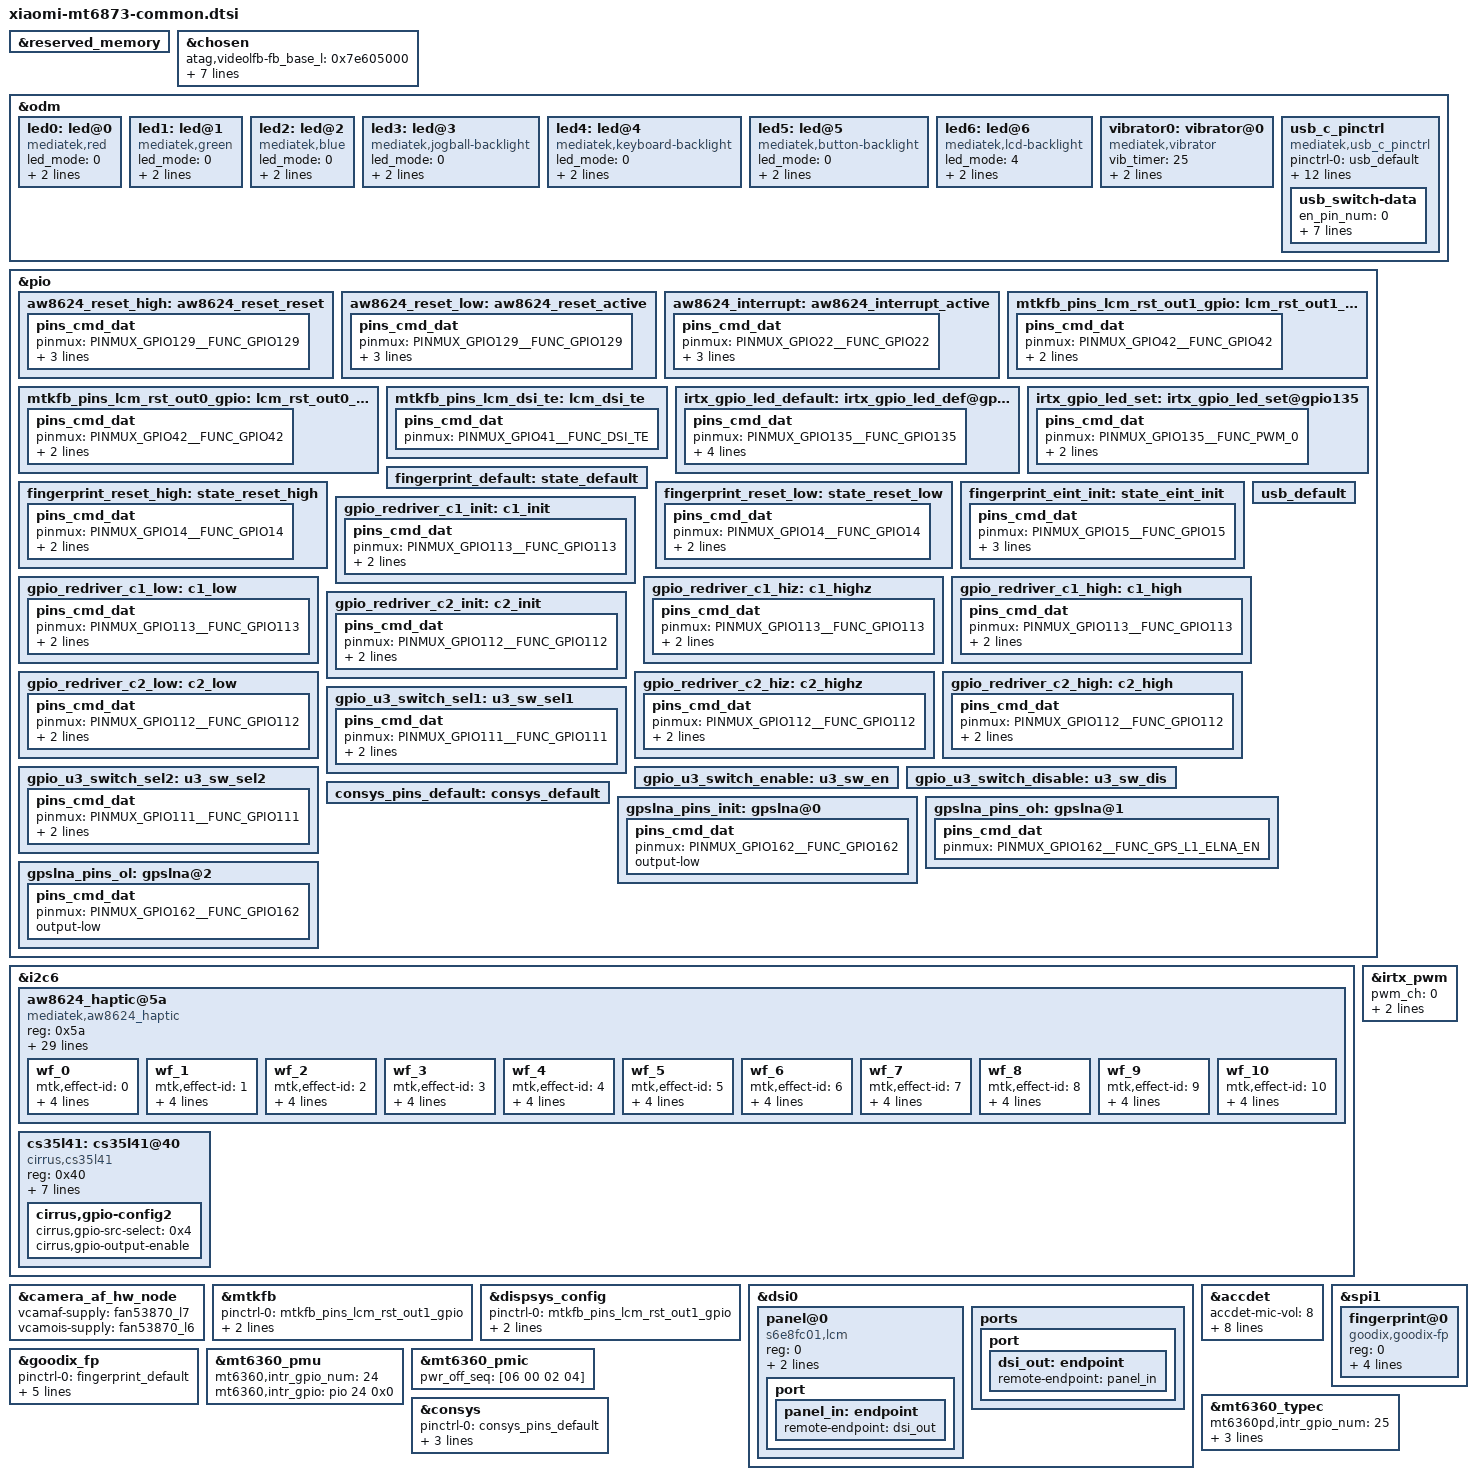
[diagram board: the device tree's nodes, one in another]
/*
 * Mediatek's mt6873 SoC device tree source
 *
 * Copyright (C) 2016 MediaTek Inc.
 * Copyright (C) 2021 XiaoMi, Inc.
 *
 * This program is free software; you can redistribute it and/or modify
 * it under the terms of the GNU General Public License version 2 as
 * published by the Free Software Foundation.
 *
 * This program is distributed in the hope that it will be useful,
 * but WITHOUT ANY WARRANTY; without even the implied warranty of
 * MERCHANTABILITY or FITNESS FOR A PARTICULAR PURPOSE.
 * See http://www.gnu.org/licenses/gpl-2.0.html for more details.
 */
/dts-v1/;
/plugin/;
#include <dt-bindings/interrupt-controller/irq.h>
#include <dt-bindings/interrupt-controller/arm-gic.h>
#include <dt-bindings/pinctrl/mt6873-pinfunc.h>

&reserved_memory {
};

/* chosen */
&chosen {

	atag,videolfb-fb_base_l = <0x7e605000>;
	atag,videolfb-fb_base_h = <0x0>;
	atag,videolfb-islcmfound = <1>;
	atag,videolfb-islcm_inited = <0>;
	atag,videolfb-fps= <6000>;
	atag,videolfb-vramSize= <0x1be0000>;
	atag,videolfb-lcmname=
		"nt35595_fhd_dsi_cmd_truly_nt50358_drv";
};

&odm {
	led0:led@0 {
		compatible = "mediatek,red";
		led_mode = <0>;
		data = <1>;
		pwm_config = <0 0 0 0 0>;
	};
	led1:led@1 {
		compatible = "mediatek,green";
		led_mode = <0>;
		data = <1>;
		pwm_config = <0 0 0 0 0>;
	};
	led2:led@2 {
		compatible = "mediatek,blue";
		led_mode = <0>;
		data = <1>;
		pwm_config = <0 0 0 0 0>;
	};
	led3:led@3 {
		compatible = "mediatek,jogball-backlight";
		led_mode = <0>;
		data = <1>;
		pwm_config = <0 0 0 0 0>;
	};
	led4:led@4 {
		compatible = "mediatek,keyboard-backlight";
		led_mode = <0>;
		data = <1>;
		pwm_config = <0 0 0 0 0>;
	};
	led5:led@5 {
		compatible = "mediatek,button-backlight";
		led_mode = <0>;
		data = <1>;
		pwm_config = <0 0 0 0 0>;
	};
	led6:led@6 {
		compatible = "mediatek,lcd-backlight";
		led_mode = <4>;
		data = <1>;
		pwm_config = <0 1 0 0 0>;
	};
	vibrator0:vibrator@0 {
		compatible = "mediatek,vibrator";
		vib_timer = <25>;
		vib_limit = <9>;
		vib_vol= <9>;
	};
	usb_c_pinctrl:usb_c_pinctrl {
		compatible = "mediatek,usb_c_pinctrl";
	};
};

/* aw8624 start */
&pio {
	aw8624_reset_high: aw8624_reset_reset {
		pins_cmd_dat {
			pinmux = <PINMUX_GPIO129__FUNC_GPIO129>;
			drive-strength = <2>;
			bias-disable;
			output-high;
		};
	};
	aw8624_reset_low: aw8624_reset_active {
		pins_cmd_dat {
			pinmux = <PINMUX_GPIO129__FUNC_GPIO129>;
			drive-strength = <2>;
			bias-disable;
			output-low;
		};
	};
	aw8624_interrupt: aw8624_interrupt_active {
		pins_cmd_dat {
			pinmux = <PINMUX_GPIO22__FUNC_GPIO22>;
			drive-strength = <2>;
			bias-pull-up;
			input-enable;
		};
	};
};

&i2c6 {
    status = "ok";
	aw8624_haptic@5a {
		compatible = "mediatek,aw8624_haptic";
		reg = <0x5a>;
		reset-gpio = <&pio 129 0x0>;
		irq-gpio = <&pio 22 0x0>;
		vib_mode = <0>; /* 0: RAM mode 1:CONT mode*/
		vib_f0_pre = < 2050 >;
		vib_f0_cali_percen = < 7 >;
		vib_cont_drv_lev = < 100 >;
		vib_cont_drv_lvl_ov = < 105 >;
		vib_cont_td = < 0xF06C >;
		vib_cont_zc_thr = < 0x08F8 >;
		vib_cont_num_brk = < 3 >;
		vib_f0_coeff = < 260 >; /*Don't modify it*/
		vib_f0_trace_parameter = < 9 3 1 31 >;
		vib_bemf_config = < 0x10 0x08 0x23 0xf8 >;
		vib_sw_brake = < 0x2c >;
		vib_tset = < 0x11 >;
		vib_func_parameter1 = < 1 >;
		vib_r_spare = < 0x68 >;
		vib_effect_id_boundary = < 10 >;
		vib_gain_flag = < 0 >;
		vib_effect_max = < 170 >;
		vib_trig_config = < 0 1 0 1 2
				0 1 0 1 2
				0 1 0 1 2 >;
		vib_bst_vol_default = < 0x1b >;
		vib_bst_vol_ram = < 0x1b >;
		vib_bst_vol_rtp = < 0x16 >;
		vib_rtp_time = < 20 20 20 20 20 20 20 20 20000 15000
				 15000 20000 25000 15000 30000 25000 20000 20000 20000 20000
				 20000 20000 20000 20000 20000 20000 20000 20000 20000 20000
				 20000 20000 20000 20000 20000 20000 20000 20000 20000 20000
				 20000 20000 20000 20000 20000 20000 20000 20000 20000 20000
				 20000 20000 20000 20000 20000 20000 20000 20000 20000 20000
				 20000 20000 20000 20000 20000 20000 20000 20000 20000 20000
				 20000 20000 20000 20000 20000 20000 20000 20000 20000 20000
				 20000 20000 20000 20000 20000 20000 20000 20000 20000 20000
				 20000 20000 20000 20000 20000 20000 20000 20000 20000 20000
				 20000 20000 20000 20000 20000 20000 20000 20000 20000 20000
				 20000 20000 20000 20000 20000 20000 20000 20000 20000 20000
				 20000 20000 20000 20000 20000 20000 20000 20000 20000 20000
				 20000 20000 20000 20000 20000 20000 20000 20000 20000 20000
				 20000 20000 20000 20000 20000 20000 20000 20000 20000 20000
				 20000 20000 20000 20000 20000 20000 20000 20000 20000 20000
				 20000 20000 20000 20000 20000 20000 20000 20000 20000 20000
				 20000 20000 20000 20000 20000 >;
		pinctrl-names = "aw8624_reset_reset","aw8624_reset_active","aw8624_interrupt_active";
		pinctrl-0 = <&aw8624_reset_low>;
		pinctrl-1 = <&aw8624_reset_high>;
		pinctrl-2 = <&aw8624_interrupt>;
		status = "ok";
		wf_0 {
			/*CLICK*/
			mtk,effect-id = <0>;
			mtk,wf-vmax-mv = <3600>;
			mtk,wf-pattern = [3e 3e];
			mtk,wf-brake-pattern = [02 01 00 00];
			mtk,wf-play-rate-us = <20000>;
		};
		wf_1 {
			/*DOUBLE CLICK*/
			mtk,effect-id = <1>;
			mtk,wf-vmax-mv = <3600>;
			mtk,wf-pattern = [7e 3e];
			mtk,wf-brake-pattern = [03 01 00 00];
			mtk,wf-play-rate-us = <20000>;
		};
		wf_2 {
			/*TICK*/
			mtk,effect-id = <2>;
			mtk,wf-vmax-mv = <3600>;
			mtk,wf-pattern = [7e 3e];
			mtk,wf-brake-pattern = [02 01 00 00];
			mtk,wf-play-rate-us = <13000>;
		};
		wf_3 {
			/*THUD*/
			mtk,effect-id = <3>;
			mtk,wf-vmax-mv = <3600>;
			mtk,wf-pattern = [3e 3e];
			mtk,wf-brake-pattern = [02 01 00 00];
			mtk,wf-play-rate-us = <10000>;
		};
		wf_4 {
			/*POP*/
			mtk,effect-id = <4>;
			mtk,wf-vmax-mv = <3600>;
			mtk,wf-pattern = [3e 3e];
			mtk,wf-brake-pattern = [02 01 00 00];
			mtk,wf-play-rate-us = <28000>;
		};
		wf_5 {
			/*HEAVY CLICK*/
			mtk,effect-id = <5>;
			mtk,wf-vmax-mv = <3600>;
			mtk,wf-pattern = [7e 7e 7e];
			mtk,wf-brake-pattern = [03 03 01 00];
			mtk,wf-play-rate-us = <10000>;
		};
		wf_6 {
			/*CLICK*/
			mtk,effect-id = <6>;
			mtk,wf-vmax-mv = <3600>;
			mtk,wf-pattern = [3e 3e];
			mtk,wf-brake-pattern = [02 01 00 00];
			mtk,wf-play-rate-us = <25000>;
		};
		wf_7 {
			/*DOUBLE CLICK*/
			mtk,effect-id = <7>;
			mtk,wf-vmax-mv = <3600>;
			mtk,wf-pattern = [7e 3e];
			mtk,wf-brake-pattern = [03 01 00 00];
			mtk,wf-play-rate-us = <25000>;
		};
		wf_8 {
			/*TICK*/
			mtk,effect-id = <8>;
			mtk,wf-vmax-mv = <3600>;
			mtk,wf-pattern = [7e 3e];
			mtk,wf-brake-pattern = [02 01 00 00];
			mtk,wf-play-rate-us = <35000>;
		};
		wf_9 {
			/*THUD*/
			mtk,effect-id = <9>;
			mtk,wf-vmax-mv = <3600>;
			mtk,wf-pattern = [3e 3e];
			mtk,wf-brake-pattern = [02 01 00 00];
			mtk,wf-play-rate-us = <15000>;
		};
		wf_10 {
			/*POP*/
			mtk,effect-id = <10>;
			mtk,wf-vmax-mv = <3600>;
			mtk,wf-pattern = [3e 3e];
			mtk,wf-brake-pattern = [02 01 00 00];
			mtk,wf-play-rate-us = <15000>;
		};
	};
};
/* aw8624 end */

/* DISPSYS GPIO standardization */

&pio {
	mtkfb_pins_lcm_rst_out1_gpio: lcm_rst_out1_gpio {
		pins_cmd_dat {
			pinmux = <PINMUX_GPIO42__FUNC_GPIO42>;
			slew-rate = <1>;
			output-high;
		};
	};

	mtkfb_pins_lcm_rst_out0_gpio: lcm_rst_out0_gpio {
		pins_cmd_dat {
			pinmux = <PINMUX_GPIO42__FUNC_GPIO42>;
			slew-rate = <1>;
			output-low;
		};
	};
	mtkfb_pins_lcm_dsi_te: lcm_dsi_te {
		pins_cmd_dat {
			pinmux = <PINMUX_GPIO41__FUNC_DSI_TE>;
		};
	};
};

&camera_af_hw_node {
	vcamaf-supply = <&fan53870_l7>;
	vcamois-supply = <&fan53870_l6>;
	status = "okay";
};

&mtkfb {
	pinctrl-names = "lcm_rst_out1_gpio", "lcm_rst_out0_gpio",
		"mode_te_te";
	pinctrl-0 = <&mtkfb_pins_lcm_rst_out1_gpio>;
	pinctrl-1 = <&mtkfb_pins_lcm_rst_out0_gpio>;
	pinctrl-2 = <&mtkfb_pins_lcm_dsi_te>;
	status = "okay";
};

&dispsys_config {
	pinctrl-names =
		"lcm_rst_out1_gpio", "lcm_rst_out0_gpio",
		"mode_te_te";
	pinctrl-0 = <&mtkfb_pins_lcm_rst_out1_gpio>;
	pinctrl-1 = <&mtkfb_pins_lcm_rst_out0_gpio>;
	pinctrl-2 = <&mtkfb_pins_lcm_dsi_te>;
	status = "okay";
};

&dsi0 {
	status = "okay";
	#address-cells = <1>;
	#size-cells = <0>;
	panel@0 {
		compatible = "s6e8fc01,lcm";
		reg = <0>;
		pm-enable-gpios = <&pio 29 0>;
		reset-gpios = <&pio 42 0>;
		pinctrl-names = "default";
		port {
			panel_in: endpoint {
				remote-endpoint = <&dsi_out>;
			};
		};
	};
	ports {
		port {
			dsi_out: endpoint {
				remote-endpoint = <&panel_in>;
			};
		};
	};
};

/* accdet start */
&accdet {
	/* accdet micbias voltage: 0x09:2.85v 0x08:2.8v 0x07,
	 * 2.7v;0x05,2.5v;0x02,1.9v
	 */
	accdet-mic-vol = <8>;
	/* accdet pwm_width, pwm_thresh, fall_delay, rise_delay
	 * debounce0, debounce1, debounce3, debounce4
	 * eint pwm_width, eint pwm_thresh
	 * eint deb(debounce0, debounce1, debounce2, debounce3), inv_debounce
	 */
	headset-mode-setting = <0x500 0x500 1 0x1f0
				0x800 0x1200 0x20 0x44
				0x4 0x1
				0x5 0x3 0x3 0x7 0xe>;
	accdet-plugout-debounce = <1>;
	/*1:ACC mode, 2:low cost without in bias, 6:low cost with in bias*/
	accdet-mic-mode = <2>;
	/*0--MD_MAX--UP_MAX--DW_MAX*/
	headset-three-key-threshold = <0 80 220 400>;
	headset-three-key-threshold-CDD = <0 121 192 600>;
	/*0--MD_MAX--VOICE_MAX--UP_MAX--DW_MAX*/
	headset-four-key-threshold = <0 58 121 192 400>;

	/* select VTH to 2v and 500k, use internal resitance */
	eint_use_ext_res = <4>;
	status = "okay";
};
/* accdet end */

/* IRTX GPIO Start */
&irtx_pwm {
	pwm_ch = <0>;
	pinctrl-names = "irtx_gpio_led_default", "irtx_gpio_led_set";
	pinctrl-0 = <&irtx_gpio_led_default>;
	pinctrl-1 = <&irtx_gpio_led_set>;
	status = "okay";
};
&pio {
	/* IRTX GPIO Settings -Start */
	/* default: GPIO0, output, high */
	irtx_gpio_led_default:irtx_gpio_led_def@gpio135 {
		pins_cmd_dat {
			pinmux = <PINMUX_GPIO135__FUNC_GPIO135>;
			slew-rate = <1>;
			bias-disable;
			output-low;
			input-schmitt-enable = <0>;
		};
	};

	irtx_gpio_led_set:irtx_gpio_led_set@gpio135 {
		pins_cmd_dat {
			pinmux = <PINMUX_GPIO135__FUNC_PWM_0>;
			slew-rate = <1>;
			output-high;
		};
	};
}; /* IRTX GPIO Settings -End */

/* FINGERPRINT start */
&spi1 {
	#address-cells = <1>;
	#size-cells = <0>;
	fingerprint@0 {
		compatible = "goodix,goodix-fp";
		reg = <0>;
		spi-max-frequency = <8000000>;
		netlink-event = <30>;
		vfp-supply = <&mt_pmic_vfp_ldo_reg>;
		power-type = <1>;
		status = "okay";
	};
};

&goodix_fp {
	pinctrl-names = "default", "reset_high", "reset_low", "eint_init";
	pinctrl-0 = <&fingerprint_default>;
	pinctrl-1 = <&fingerprint_reset_high>;
	pinctrl-2 = <&fingerprint_reset_low>;
	pinctrl-3 = <&fingerprint_eint_init>;
	interrupt-parent = <&pio>;
	interrupts = <15 IRQ_TYPE_EDGE_RISING 15 0>;
	status = "okay";
};

&pio {
	fingerprint_default: state_default {
	};
	fingerprint_reset_high: state_reset_high {
		pins_cmd_dat {
			pinmux = <PINMUX_GPIO14__FUNC_GPIO14>;
			slew-rate = <1>;
			output-high;
		};
	};
	fingerprint_reset_low: state_reset_low {
		pins_cmd_dat {
			pinmux = <PINMUX_GPIO14__FUNC_GPIO14>;
			slew-rate = <1>;
			output-low;
		};
	};
	fingerprint_eint_init: state_eint_init {
		pins_cmd_dat {
			pinmux = <PINMUX_GPIO15__FUNC_GPIO15>;
			slew-rate = <0>;
			bias-pull-up = <MTK_PUPD_SET_R1R0_10>;
			input-schmitt-enable;
		};
	};
};
/* FINGERPRINT end */

&mt6360_pmu {
	mt6360,intr_gpio_num = <24>; /* direct defined GPIO num */
	mt6360,intr_gpio = <&pio 24 0x0>;
};

&mt6360_pmic {
	pwr_off_seq = [06 00 02 04];
};

&mt6360_typec {
	mt6360pd,intr_gpio_num = <25>; /* direct defined GPIO num */
	mt6360pd,intr_gpio = <&pio 25 0x0>;
	mt6360pd,pcb_gpio = <&pio 19 0x0>;
	mt6360pd,pcb_gpio_num = <19>;
};

/* USB SWITCH GPIO start */
&pio {
	usb_default: usb_default {
	};

	gpio_redriver_c1_init: c1_init {
		pins_cmd_dat {
			pinmux = <PINMUX_GPIO113__FUNC_GPIO113>;
			slew-rate = <1>;
			output-low;
		};
	};

	gpio_redriver_c1_low: c1_low {
		pins_cmd_dat {
			pinmux = <PINMUX_GPIO113__FUNC_GPIO113>;
			slew-rate = <1>;
			output-low;
		};
	};

	gpio_redriver_c1_hiz: c1_highz {
		pins_cmd_dat {
			pinmux = <PINMUX_GPIO113__FUNC_GPIO113>;
			slew-rate= <0>;
			bias-disable;
		};
	};

	gpio_redriver_c1_high: c1_high {
		pins_cmd_dat {
			pinmux = <PINMUX_GPIO113__FUNC_GPIO113>;
			slew-rate = <1>;
			output-high;
		};
	};

	gpio_redriver_c2_init: c2_init {
		pins_cmd_dat {
			pinmux = <PINMUX_GPIO112__FUNC_GPIO112>;
			slew-rate = <1>;
			output-low;
		};
	};

	gpio_redriver_c2_low: c2_low {
		pins_cmd_dat {
			pinmux = <PINMUX_GPIO112__FUNC_GPIO112>;
			slew-rate = <1>;
			output-low;
		};
	};

	gpio_redriver_c2_hiz: c2_highz {
		pins_cmd_dat {
			pinmux = <PINMUX_GPIO112__FUNC_GPIO112>;
			slew-rate= <0>;
			bias-disable;
		};
	};

	gpio_redriver_c2_high: c2_high {
		pins_cmd_dat {
			pinmux = <PINMUX_GPIO112__FUNC_GPIO112>;
			slew-rate = <1>;
			output-high;
		};
	};

	gpio_u3_switch_sel1: u3_sw_sel1 {
		pins_cmd_dat {
			pinmux = <PINMUX_GPIO111__FUNC_GPIO111>;
			slew-rate = <1>;
			output-low;
		};
	};

	gpio_u3_switch_sel2: u3_sw_sel2 {
		pins_cmd_dat {
			pinmux = <PINMUX_GPIO111__FUNC_GPIO111>;
			slew-rate = <1>;
			output-high;
		};
	};

	gpio_u3_switch_enable: u3_sw_en {
	};

	gpio_u3_switch_disable: u3_sw_dis {
	};
};

&usb_c_pinctrl {
	pinctrl-names = "usb_default",
		"redrv_c1_init",
		"redrv_c1_low",
		"redrv_c1_hiz",
		"redrv_c1_high",
		"redrv_c2_init",
		"redrv_c2_low",
		"redrv_c2_hiz",
		"redrv_c2_high",
		"switch_sel1",
		"switch_sel2",
		"switch_enable",
		"switch_disable";

	pinctrl-0 = <&usb_default>;
	pinctrl-1 = <&gpio_redriver_c1_init>;
	pinctrl-2 = <&gpio_redriver_c1_low>;
	pinctrl-3 = <&gpio_redriver_c1_hiz>;
	pinctrl-4 = <&gpio_redriver_c1_high>;
	pinctrl-5 = <&gpio_redriver_c2_init>;
	pinctrl-6 = <&gpio_redriver_c2_low>;
	pinctrl-7 = <&gpio_redriver_c2_hiz>;
	pinctrl-8 = <&gpio_redriver_c2_high>;
	pinctrl-9 = <&gpio_u3_switch_sel1>;
	pinctrl-10 = <&gpio_u3_switch_sel2>;
	pinctrl-11 = <&gpio_u3_switch_enable>;
	pinctrl-12 = <&gpio_u3_switch_disable>;
	status = "okay";

	usb_switch-data {
		en_pin_num = <0>;
		en_pin_val = <0>;
		sel_pin_num = <111>;
		sel_pin_val = <1>;
		c1_pin_num = <113>;
		c1_pin_val = <2>;
		c2_pin_num = <112>;
		c2_pin_val = <1>;
	};
};
/* USB SWITCH GPIO end */

/* CONSYS GPIO standardization */
&pio {
	consys_pins_default: consys_default {
	};
	gpslna_pins_init: gpslna@0 {
		pins_cmd_dat {
			pinmux = <PINMUX_GPIO162__FUNC_GPIO162>;
			output-low;
		};
	};
	gpslna_pins_oh: gpslna@1 {
		pins_cmd_dat {
			pinmux = <PINMUX_GPIO162__FUNC_GPS_L1_ELNA_EN>;
		};
	};
	gpslna_pins_ol: gpslna@2 {
		pins_cmd_dat {
			pinmux = <PINMUX_GPIO162__FUNC_GPIO162>;
			output-low;
		};
	};
};
&consys {
	pinctrl-names = "default", "gps_lna_state_init",
		"gps_lna_state_oh", "gps_lna_state_ol";
	pinctrl-0 = <&consys_pins_default>;
	pinctrl-1 = <&gpslna_pins_init>;
	pinctrl-2 = <&gpslna_pins_oh>;
	pinctrl-3 = <&gpslna_pins_ol>;
	status = "okay";
};
/* CONSYS end */
/* Audio Start */
&i2c6 {
       status = "okay";
       cs35l41: cs35l41@40 {
               compatible = "cirrus,cs35l41";
               reg = <0x40>;
               reset-gpio = <&pio 30 0>;
               interrupt-parent = <&pio>;
               interrupts = <31 IRQ_TYPE_LEVEL_LOW 31 0>;
               irq-gpio = <&pio 31 0>;
               cirrus,boost-peak-milliamp = <4500>;
               cirrus,boost-ind-nanohenry = <1000>;
               cirrus,boost-cap-microfarad = <15>;
               cirrus,gpio-config2 {
                       cirrus,gpio-src-select = <0x4>;
                       cirrus,gpio-output-enable;
               };
       };
};
/* Audio End */
#include "mediatek/cust_mt6873_camera.dtsi"
#include "mediatek/cust_mt6873_touch_1080x2280.dtsi"
#include <k6873v1_64/cust.dtsi>
/*End of this file, DO NOT ADD ANYTHING HERE*/
